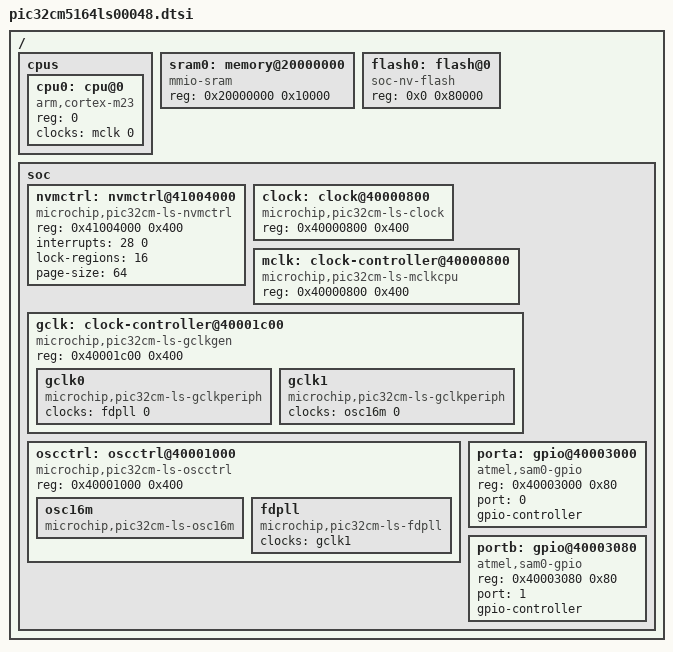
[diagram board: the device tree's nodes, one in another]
/*
 * Copyright (c) 2026 Microchip Technology Inc.
 * SPDX-License-Identifier: Apache-2.0
 */

#include <arm/armv8-m.dtsi>

/ {
	cpus {
		#address-cells = <1>;
		#size-cells = <0>;

		cpu0: cpu@0 {
			device_type = "cpu";
			compatible = "arm,cortex-m23";
			reg = <0>;
			#address-cells = <1>;
			#size-cells = <1>;
			clocks = <&mclk 0>;
		};
	};

	sram0: memory@20000000 {
		compatible = "mmio-sram";
		reg = <0x20000000 0x10000>; /* 64KB for 5164 */
	};

	flash0: flash@0 {
		compatible = "soc-nv-flash";
		reg = <0x0 0x80000>; /* 512KB for 5164 */
	};

	soc {
		nvmctrl: nvmctrl@41004000 {
			compatible = "microchip,pic32cm-ls-nvmctrl", "atmel,sam0-nvmctrl";
			reg = <0x41004000 0x400>;
			interrupts = <28 0>;
			lock-regions = <16>;
			page-size = <64>;
		};

		clock: clock@40000800 {
			compatible = "microchip,pic32cm-ls-clock";
			reg = <0x40000800 0x400>;
			#clock-cells = <1>;
			status = "okay";
		};

		mclk: clock-controller@40000800 {
			compatible = "microchip,pic32cm-ls-mclkcpu";
			reg = <0x40000800 0x400>;
			#clock-cells = <1>;
		};

		gclk: clock-controller@40001c00 {
			compatible = "microchip,pic32cm-ls-gclkgen";
			reg = <0x40001c00 0x400>;
			#clock-cells = <1>;

			gclk0: gclk0 {
				compatible = "microchip,pic32cm-ls-gclkperiph";
				clocks = <&fdpll 0>;
				#clock-cells = <0>;
			};

			gclk1: gclk1 {
				compatible = "microchip,pic32cm-ls-gclkperiph";
				clocks = <&osc16m 0>;
				#clock-cells = <0>;
			};
		};

		oscctrl: oscctrl@40001000 {
			compatible = "microchip,pic32cm-ls-oscctrl";
			reg = <0x40001000 0x400>;
			#clock-cells = <1>;

			osc16m: osc16m {
				compatible = "microchip,pic32cm-ls-osc16m";
				#clock-cells = <0>;
			};

			fdpll: fdpll {
				compatible = "microchip,pic32cm-ls-fdpll";
				clocks = <&gclk1>;
				#clock-cells = <0>;
			};
		};

		porta: gpio@40003000 {
			compatible = "atmel,sam0-gpio";
			reg = <0x40003000 0x80>;
			port = <0>;
			gpio-controller;
			#gpio-cells = <2>;
		};

		portb: gpio@40003080 {
			compatible = "atmel,sam0-gpio";
			reg = <0x40003080 0x80>;
			port = <1>;
			gpio-controller;
			#gpio-cells = <2>;
		};
	};
};
